# XMC4300 register map
Vendor: Infineon; File version: 1.1.0 (Reference Manual v1.1)
CPU: CM4 r2p0, little endian, MPU, FPU, 6 interrupt priority bits
Registers are 32-bit, read-write, reset 0x0 unless marked. A register's access mark holds for its fields unless they carry their own. Offsets are from the block's base; [hi:lo] are bit positions.

## FCE_KE0 — Flexible CRC Engine
Base 0x50020020
Same registers: FCE_KE1 0x50020040, FCE_KE2 0x50020060, FCE_KE3 0x50020080
0x00 IR — Input Register
0x04 RES ro reset 0xFFFFFFFF — CRC Result Register
  [31:0] RES — Result Register
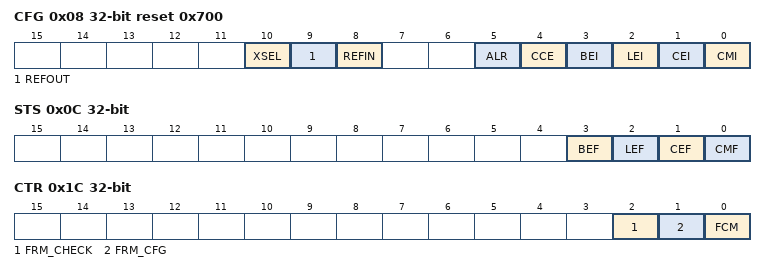
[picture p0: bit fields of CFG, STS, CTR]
0x08 CFG reset 0x700 — CRC Configuration Register
  [10] XSEL — Selects the value to be xored with the final CRC
    0=0x00000000; 1=0xFFFFFFFF
  [9] REFOUT — CRC 32-Bit Wise Reflection
    0=CRC 32-bit wise is disabled; 1=CRC 32-bit wise is enabled
  [8] REFIN — IR Byte Wise Reflection
    0=IR Byte Wise Reflection is disabled; 1=IR Byte Wise Reflection is enabled
  [5] ALR — Automatic Length Reload
    0=Disables automatic reload of the LENGTH field; 1=Enables automatic reload of the LENGTH field at the end of a message
  [4] CCE — CRC Check Comparison
    0=CRC check comparison at the end of a message is disabled; 1=CRC check comparison at the end of a message is enabled
  [3] BEI — Bus Error Interrupt
    0=Bus Error Interrupt is disabled; 1=Bus Error Interrupt is enabled
  [2] LEI — Length Error Interrupt
    0=Length Error Interrupt is disabled; 1=Length Error Interrupt is enabled
  [1] CEI — Configuration Error Interrupt
    0=Configuration Error Interrupt is disabled; 1=Configuration Error Interrupt is enabled
  [0] CMI — CRC Mismatch Interrupt
    0=CRC Mismatch Interrupt is disabled; 1=CRC Mismatch Interrupt is enabled
0x0C STS — CRC Status Register
  [3] BEF — Bus Error Flag
  [2] LEF — Length Error Flag
  [1] CEF — Configuration Error Flag
  [0] CMF — CRC Mismatch Flag
0x10 LENGTH — CRC Length Register
  [15:0] LENGTH — Message Length Register
0x14 CHECK — CRC Check Register
0x18 CRC
0x1C CTR — CRC Test Register
  [2] FRM_CHECK — Force Check Register Mismatch
  [1] FRM_CFG — Force CFG Register Mismatch
  [0] FCM — Force CRC Mismatch

## PBA0 — Peripheral Bridge AHB 0
Base 0x40000000
Same registers: PBA1 0x48000000
0x00 STS — Peripheral Bridge Status Register
  [0] WERR — Bufferable Write Access Error
    0=no write error occurred; 1=write error occurred, interrupt request is pending
0x04 WADDR ro — PBA Write Error Address Register
  [31:0] WADDR — Write Error Address

## PREF — Prefetch Unit
Base 0x58004000
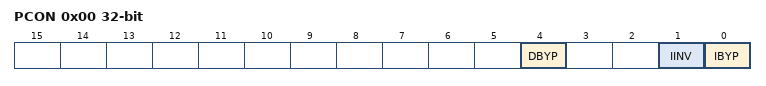
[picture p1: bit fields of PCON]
0x00 PCON access per field — Prefetch Configuration Register
  [4] DBYP rw — Data Buffer Bypass
    0=Prefetch Data buffer not bypassed; 1=Prefetch Data buffer bypassed
  [1] IINV wo — Instruction Prefetch Buffer Invalidate
    0=Const_0 (No effect.); 1=Const_1 (Initiate invalidation of entire instruction cache.)
  [0] IBYP rw — Instruction Prefetch Buffer Bypass
    0=Const_0 (Instruction prefetch buffer not bypassed.); 1=Const_1 (Instruction prefetch buffer bypassed.)

## PMU0 — Program Management Unit
Base 0x58000508
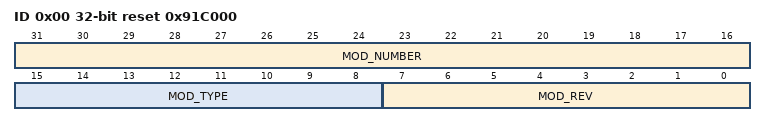
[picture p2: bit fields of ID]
0x00 ID ro reset 0x91C000 (reset mask 0xFFFFFF00) — PMU0 Identification Register
  [31:16] MOD_NUMBER — Module Number Value
  [15:8] MOD_TYPE — Module Type
  [7:0] MOD_REV — Module Revision Number

## WDT — Watch Dog Timer
Base 0x50008000
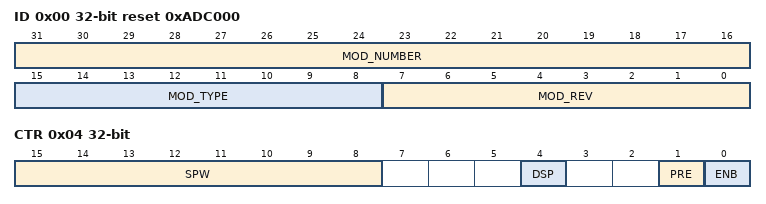
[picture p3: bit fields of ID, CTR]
0x00 ID ro reset 0xADC000 (reset mask 0xFFFFFF00) — WDT ID Register
  [31:16] MOD_NUMBER — Module Number
  [15:8] MOD_TYPE — Module Type
  [7:0] MOD_REV — Module Revision
0x04 CTR — WDT Control Register
  [15:8] SPW — Service Indication Pulse Width
  [4] DSP — Debug Suspend
  [1] PRE — Pre-warning
  [0] ENB — Enable
0x08 SRV wo — WDT Service Register
  [31:0] SRV — Service
0x0C TIM ro — WDT Timer Register
  [31:0] TIM — Timer Value
0x10 WLB — WDT Window Lower Bound Register
  [31:0] WLB — Window Lower Bound
0x14 WUB reset 0xFFFFFFFF — WDT Window Upper Bound Register
  [31:0] WUB — Window Upper Bound
0x18 WDTSTS ro — WDT Status Register
  [0] ALMS — Pre-warning Alarm
0x1C WDTCLR wo — WDT Clear Register
  [0] ALMC — Pre-warning Alarm

## Notices in the file
Copyright (c) 2016, Infineon Technologies AG
All rights reserved.
Redistribution and use in source and binary forms, with or without modification,are permitted provided that the
following conditions are met:
Redistributions of source code must retain the above copyright notice, this list of conditions and the following
disclaimer.
Redistributions in binary form must reproduce the above copyright notice, this list of conditions and the following
disclaimer in the documentation and/or other materials provided with the distribution.
Neither the name of the copyright holders nor the names of its contributors may be used to endorse or promote
products derived from this software without specific prior written permission.
THIS SOFTWARE IS PROVIDED BY THE COPYRIGHT HOLDERS AND CONTRIBUTORS "AS IS" AND ANY EXPRESS OR IMPLIED WARRANTIES,
INCLUDING, BUT NOT LIMITED TO, THE IMPLIED WARRANTIES OF MERCHANTABILITY AND FITNESS FOR A PARTICULAR PURPOSE ARE
DISCLAIMED. IN NO EVENT SHALL THE COPYRIGHT HOLDER OR CONTRIBUTORS BE LIABLE  FOR ANY DIRECT, INDIRECT, INCIDENTAL,
SPECIAL, EXEMPLARY, OR CONSEQUENTIAL DAMAGES (INCLUDING, BUT NOT LIMITED TO, PROCUREMENT OF SUBSTITUTE GOODS OR
SERVICES; LOSS OF USE, DATA, OR PROFITS; OR BUSINESS INTERRUPTION) HOWEVER CAUSED AND ON ANY THEORY OF LIABILITY,
WHETHER IN CONTRACT, STRICT LIABILITY,OR TORT (INCLUDING NEGLIGENCE OR OTHERWISE) ARISING IN ANY WAY OUT OF THE USE
OF THIS SOFTWARE, EVEN IF ADVISED OF THE POSSIBILITY OF SUCH DAMAGE.
